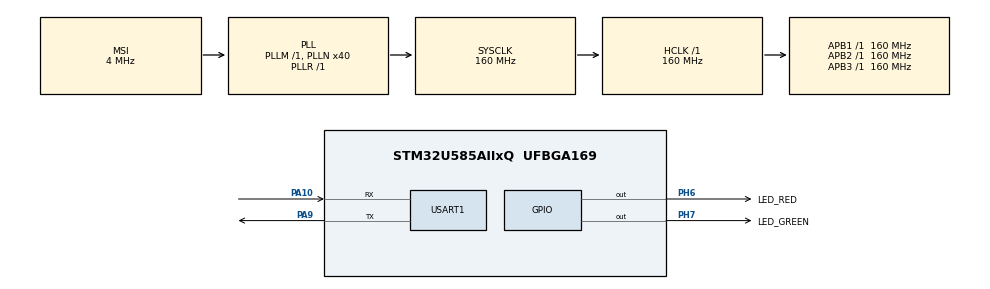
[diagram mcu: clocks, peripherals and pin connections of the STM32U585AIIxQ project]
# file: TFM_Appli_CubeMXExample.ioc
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CORTEX_M33_NS.userName=CORTEX_M33
Mcu.Family=STM32U5
Mcu.Name=STM32U585AIIxQ
Mcu.Package=UFBGA169
NVIC.PriorityGroup=NVIC_PRIORITYGROUP_4
NVIC.TIM6_IRQn=true\:15\:0\:false\:false\:true\:false\:false\:true\:true
NVIC.TimeBase=TIM6_IRQn
NVIC.TimeBaseIP=TIM6
PA10.Mode=Asynchronous
PA10.Signal=USART1_RX
PA9.Mode=Asynchronous
PA9.Signal=USART1_TX
PH6.GPIO_Label=LED_RED
PH6.Signal=GPIO_Output
PH7.GPIO_Label=LED_GREEN
PH7.Signal=GPIO_Output
PWR.PowerMode=PWR_SMPS_SUPPLY
ProjectManager.HeapSize=0x200
ProjectManager.StackSize=0x400
ProjectManager.TargetToolchain=STM32CubeIDE
RCC.ADCFreq_Value=16000000
RCC.AHBFreq_Value=160000000
RCC.APB1Freq_Value=160000000
RCC.APB1TimFreq_Value=160000000
RCC.APB2Freq_Value=160000000
RCC.APB2TimFreq_Value=160000000
RCC.APB3Freq_Value=160000000
RCC.CortexFreq_Value=160000000
RCC.DACCLockSelectionVirtual=RCC_DAC1CLKSOURCE_LSI
RCC.DACCLockSelectionVirtualString=RCC_DAC1CLKSOURCE_LSI
RCC.EPOD_VALUE=4000000
RCC.HCLKFreq_Value=160000000
RCC.HSE_VALUE=16000000
RCC.HSI48_VALUE=48000000
RCC.HSI_VALUE=16000000
RCC.LSE_VALUE=32768
RCC.LSIDIV_VALUE=32000
RCC.MSI_VALUE=4000000
RCC.PLL1R=1
RCC.PLLFRACN=0
RCC.PLLN=40
RCC.SYSCLKFreq_VALUE=160000000
RCC.SYSCLKSource=RCC_SYSCLKSOURCE_PLLCLK
RCC.USBFreq_Value=48000000
RCC.VCOOutputFreq_Value=160000000
THREADX.TX_APP_MEM_POOL_SIZE=(1024*4)
USART1.VirtualMode-Asynchronous=VM_ASYNC
VP_ICACHE_VS_ICACHE.Mode=DirectMappedCache
VP_LPBAMQUEUE_VS_QUEUE.Mode=QUEUEMODE
VP_LPBAM_VS_SIG1.Mode=SmartRun
VP_LPBAM_VS_SIG4.Mode=LPDMA1
VP_PWR_VS_DBSignals.Mode=DisableDeadBatterySignals
VP_PWR_VS_LPOM.Mode=PowerOptimisation
VP_PWR_VS_SECSignals.Mode=Security/Privilege
VP_SYS_VS_tim6.Mode=TIM6
VP_THREADX_VS_RTOSJjThreadXJjCoreJjDefault.Mode=Core_Default
board=custom

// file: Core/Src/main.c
/* USER CODE BEGIN Header */
/**
  ******************************************************************************
  * @file           : main.c
  * @brief          : Main program body
  ******************************************************************************
  * @attention
  *
  * Copyright (c) 2022 STMicroelectronics.
  * All rights reserved.
  *
  * This software is licensed under terms that can be found in the LICENSE file
  * in the root directory of this software component.
  * If no LICENSE file comes with this software, it is provided AS-IS.
  *
  ******************************************************************************
  */
/* USER CODE END Header */
#include "main.h"
#include "app_threadx.h"
#include "icache.h"
#include "usart.h"
#include "gpio.h"

/* USER CODE BEGIN Includes */
#include "stdio.h"
/* USER CODE END Includes */

void SystemClock_Config(void);
static void SystemPower_Config(void);

int main(void)
{

  /* MCU Configuration--------------------------------------------------------*/

  /* Reset of all peripherals, Initializes the Flash interface and the Systick. */
  HAL_Init();

  /* Initialize all configured peripherals */
  MX_GPIO_Init();
  MX_USART1_UART_Init();
  MX_ICACHE_Init();
  /* USER CODE BEGIN 2 */

  printf("Non secure appli starting ...\r\n");
  /* USER CODE END 2 */

  MX_ThreadX_Init();

  /* We should never get here as control is now taken by the scheduler */
  /* Infinite loop */
  while (1)
  {

  }
}

void SystemClock_Config(void)
{
  RCC_OscInitTypeDef RCC_OscInitStruct = {0};
  RCC_ClkInitTypeDef RCC_ClkInitStruct = {0};

  /** Configure the main internal regulator output voltage
  */
  if (HAL_PWREx_ControlVoltageScaling(PWR_REGULATOR_VOLTAGE_SCALE1) != HAL_OK)
  {
    Error_Handler();
  }

  /** Initializes the CPU, AHB and APB busses clocks
  */
  RCC_OscInitStruct.OscillatorType = RCC_OSCILLATORTYPE_MSI;
  RCC_OscInitStruct.MSIState = RCC_MSI_ON;
  RCC_OscInitStruct.MSICalibrationValue = RCC_MSICALIBRATION_DEFAULT;
  RCC_OscInitStruct.MSIClockRange = RCC_MSIRANGE_4;
  RCC_OscInitStruct.PLL.PLLState = RCC_PLL_ON;
  RCC_OscInitStruct.PLL.PLLSource = RCC_PLLSOURCE_MSI;
  RCC_OscInitStruct.PLL.PLLMBOOST = RCC_PLLMBOOST_DIV1;
  RCC_OscInitStruct.PLL.PLLM = 1;
  RCC_OscInitStruct.PLL.PLLN = 40;
  RCC_OscInitStruct.PLL.PLLP = 2;
  RCC_OscInitStruct.PLL.PLLQ = 2;
  RCC_OscInitStruct.PLL.PLLR = 1;
  RCC_OscInitStruct.PLL.PLLRGE = RCC_PLLVCIRANGE_0;
  RCC_OscInitStruct.PLL.PLLFRACN = 0;
  if (HAL_RCC_OscConfig(&RCC_OscInitStruct) != HAL_OK)
  {
    Error_Handler();
  }

  /** Initializes the CPU, AHB and APB busses clocks
  */
  RCC_ClkInitStruct.ClockType = RCC_CLOCKTYPE_HCLK|RCC_CLOCKTYPE_SYSCLK
                              |RCC_CLOCKTYPE_PCLK1|RCC_CLOCKTYPE_PCLK2
                              |RCC_CLOCKTYPE_PCLK3;
  RCC_ClkInitStruct.SYSCLKSource = RCC_SYSCLKSOURCE_PLLCLK;
  RCC_ClkInitStruct.AHBCLKDivider = RCC_SYSCLK_DIV1;
  RCC_ClkInitStruct.APB1CLKDivider = RCC_HCLK_DIV1;
  RCC_ClkInitStruct.APB2CLKDivider = RCC_HCLK_DIV1;
  RCC_ClkInitStruct.APB3CLKDivider = RCC_HCLK_DIV1;

  if (HAL_RCC_ClockConfig(&RCC_ClkInitStruct, FLASH_LATENCY_4) != HAL_OK)
  {
    Error_Handler();
  }
}

/**
  * @brief Power Configuration
  * @retval None
  */
static void SystemPower_Config(void)
{

  /*
   * Disable the internal Pull-Up in Dead Battery pins of UCPD peripheral
   */
  HAL_PWREx_DisableUCPDDeadBattery();

  /*
   * Switch to SMPS regulator instead of LDO
   */
  if (HAL_PWREx_ConfigSupply(PWR_SMPS_SUPPLY) != HAL_OK)
  {
    Error_Handler();
  }
}

void HAL_TIM_PeriodElapsedCallback(TIM_HandleTypeDef *htim)
{
  if (htim->Instance == TIM6) {
    HAL_IncTick();
  }
}

void Error_Handler(void)
{
  __disable_irq();
  while (1)
  {
  }
}
